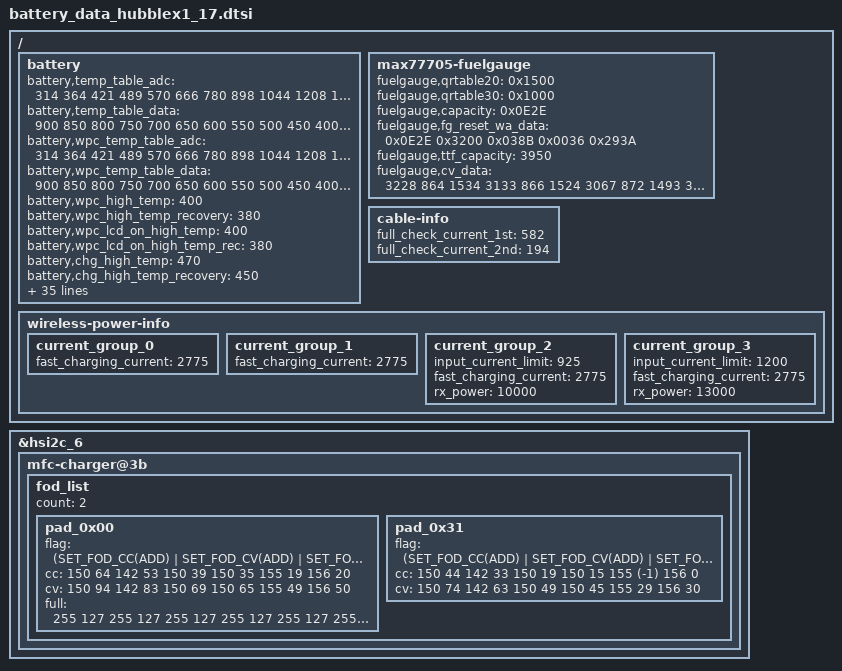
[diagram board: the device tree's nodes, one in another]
/* SAMSUNG UNIVERSAL9830 board device tree source
 *
 * Copyright (c) 2018 Samsung Electronics Co., Ltd.
 *		http://www.samsung.com
 *
 * This program is free software; you can redistribute it and/or modify
 * it under the terms of the GNU General Public License version 2 as
 * published by the Free Software Foundation.
 */

#include "battery_data_hubble_common.dtsi"

/ {
	fragment@battery {
		target-path = "/";
		__overlay__ {
			battery {
				battery,temp_table_adc = <
					314 364 421 489 570 666 780 898 1044 1208 1396 1598 1817
					2049 2286 2518 2752 2965 3159 3341 3494 3606 3704>;

				battery,temp_table_data = <
					900 850 800 750 700 650 600 550 500 450 400 350 300 250
					200 150 100 50 0 (-50) (-100) (-150) (-200)>;

				battery,wpc_temp_table_adc = <
					314 364 421 489 570 666 780 898 1044 1208 1396 1598 1817
					2049 2286 2518 2752 2965 3159 3341 3494 3606 3704>;

				battery,wpc_temp_table_data = <
					900 850 800 750 700 650 600 550 500 450 400 350 300 250
					200 150 100 50 0 (-50) (-100) (-150) (-200)>;

				battery,wpc_high_temp = <400>;
				battery,wpc_high_temp_recovery = <380>;
				battery,wpc_lcd_on_high_temp = <400>;
				battery,wpc_lcd_on_high_temp_rec = <380>;

				battery,chg_high_temp = <470>;
				battery,chg_high_temp_recovery = <450>;

				battery,dchg_high_temp = <500>;
				battery,dchg_high_temp_recovery = <440>;
				battery,dchg_high_batt_temp = <400>;
				battery,dchg_high_batt_temp_recovery = <380>;

				/* swelling current */
				battery,swelling_low_temp_current = <900>;	/* 0.24C */
				battery,swelling_low_temp_current_2nd = <350>;	/* 0.1C */
				battery,swelling_low_temp_current_3rd = <2750>;	/* 0.72C */
				battery,swelling_low_temp_topoff = <194>;	/* 0.05C */
				battery,swelling_high_temp_current = <1350>;	/* 0.36C */
				battery,swelling_high_temp_topoff = <194>;	/* 0.05C */
				battery,swelling_wc_high_temp_current = <900>;	/* 0.24C */
				battery,swelling_wc_low_temp_current = <900>;	/* 0.24C */
 				battery,swelling_wc_low_temp_current_2nd = <350>;	/* 0.1C */
				battery,swelling_wc_low_temp_current_3rd = <2750>;	/* 0.72C */

				/* step charging option */
				battery,step_charging_type = <0x3E>;
				battery,step_charging_step = <2>;
				battery,step_charging_charge_power = <12000>;
				battery,step_charging_condition = <55 100 55 100 55 100 55 100 55 100>;
				battery,step_charging_condition_curr = <2850 2400>;
				battery,step_charging_current = <3150 2850>;
				battery,step_charging_float_voltage = <4210 4380>;

				/* direct step charging option */
				battery,dc_step_chg_type = <0x6B>; /* origin(0x6B) */
				battery,dc_step_chg_charge_power = <22000>;
				battery,dc_step_chg_step = <3>;
				battery,dc_step_chg_cond_vol = <4110 4210 4380>; /* STEP_CHARGING_CONDITION_VOLTAGE */ 
				battery,dc_step_chg_cond_iin = <1800 1610 0>; /* STEP_CHARGING_CONDITION_INPUT_CURRENT */
				battery,dc_step_chg_iin_check_cnt = <3>;
				battery,dc_step_chg_cond_soc = <25 55 100 25 55 100 25 55 100 25 55 100 25 55 100>; /* STEP_CHARGING_CONDITION_SOC */
				battery,dc_step_chg_val_vfloat = <4110 4210 4380>; /* STEP_CHARGING_CONDITION_FLOAT_VOLTAGE */
				battery,dc_step_chg_val_iout = <4690 3600 3220>;

				battery,snkcap_data = /bits/ 8 <0x04 0x2C 0x91 0x01 0x36 0xC8 0xD0 0x02 0x00 0xC8 0x90
								0x41 0x8B 0x2F 0x21 0xDC 0xC0>;
			};

			max77705-fuelgauge {
				status = "okay";
				fuelgauge,qrtable20 = <0x1500>;
				fuelgauge,qrtable30 = <0x1000>;
				fuelgauge,capacity = <0x0E2E>;
				/* fullcapnom(=capacity), dPacc, dQacc,  rcomp0, tempco */
				fuelgauge,fg_reset_wa_data = <0x0E2E 0x3200 0x038B 0x0036 0x293A>;
				fuelgauge,ttf_capacity = <3950>;
				fuelgauge,cv_data = <
					3228	864	1534
					3133	866	1524
					3067	872	1493
					3019	874	1483
					2929	879	1452
					2896	881	1442
					2843	883	1431
					2792	885	1421
					2754	887	1411
					2695	892	1380
					2660	893	1370
					2625	895	1360
					2580	897	1349
					2531	898	1339
					2492	902	1319
					2450	903	1309
					2410	905	1298
					2348	908	1278
					2296	909	1268
					2263	910	1257
					2214	915	1227
					2182	916	1216
					2147	919	1196
					2103	920	1186
					2051	922	1175
					2019	924	1155
					1981	927	1134
					1948	928	1124
					1911	930	1104
					1879	932	1093
					1834	933	1083
					1795	935	1063
					1761	938	1032
					1722	942	1001
					1689	944	981
					1649	946	960
					1592	948	940
					1532	950	919
					1493	954	878
					1462	955	868
					1410	958	827
					1362	959	817
					1338	960	807
					1291	964	756
					1264	968	715
					1237	968	704
					1213	969	694
					1169	974	633
					1127	975	622
					1105	975	612
					1073	980	541
					1049	982	510
					1010	983	489
					993		984	479
					972		986	448
					955		988	407
					932		990	387
					881		990	377
					864		996	356
					761		1000	307
					710		1000	297
					688		1000	287
					668		1000	235
					658		1000	215
					647		1000	184
					635		1000	153
					622		1000	123
					610		1000	92
					596		1000	61
					583		1000	31
					571		1000	0
				>;
			};

			cable-info {
				full_check_current_1st = <582>;
				full_check_current_2nd = <194>;
			};

			wireless-power-info {
				current_group_0 {
					fast_charging_current = <2775>;
				};
				current_group_1 {
					fast_charging_current = <2775>;
				};
				current_group_2 {
					input_current_limit = <925>;
					fast_charging_current = <2775>;
					rx_power = <10000>;
				};
				current_group_3 {
					input_current_limit = <1200>;
					fast_charging_current = <2775>;
					rx_power = <13000>;
				};
			};
		}; /* end of __overlay__ */
	}; /* end of fragment */
};

#define FOD_FLAG_NONE			0
#define FOD_FLAG_ADD			1
#define FOD_FLAG_USE_CC			2
#define FOD_FLAG_USE_DEFAULT	3
#define SET_FOD_CC(_flag)		(FOD_FLAG_ ##_flag)
#define SET_FOD_CV(_flag)		(FOD_FLAG_ ##_flag << 4)
#define SET_FOD_FULL(_flag)		(FOD_FLAG_ ##_flag << 8)

&hsi2c_6 {
	mfc-charger@3b {
		fod_list {
			count = <2>;

			pad_0x00 { /* DEFAULT */
				flag = <(SET_FOD_CC(ADD) | SET_FOD_CV(ADD) | SET_FOD_FULL(ADD))>;
				cc = <150 64 142 53 150 39 150 35 155 19 156 20>;
				cv = <150 94 142 83 150 69 150 65 155 49 156 50>;
				full = <255 127 255 127 255 127 255 127 255 127 255 127>;
			};

			pad_0x31 { /* DREAM PAD(V) */
				flag = <(SET_FOD_CC(ADD) | SET_FOD_CV(ADD) | SET_FOD_FULL(USE_DEFAULT))>;
				cc = <150 44 142 33 150 19 150 15 155 (-1) 156 0>;
				cv = <150 74 142 63 150 49 150 45 155 29 156 30>;
			};
		};
	};
};
